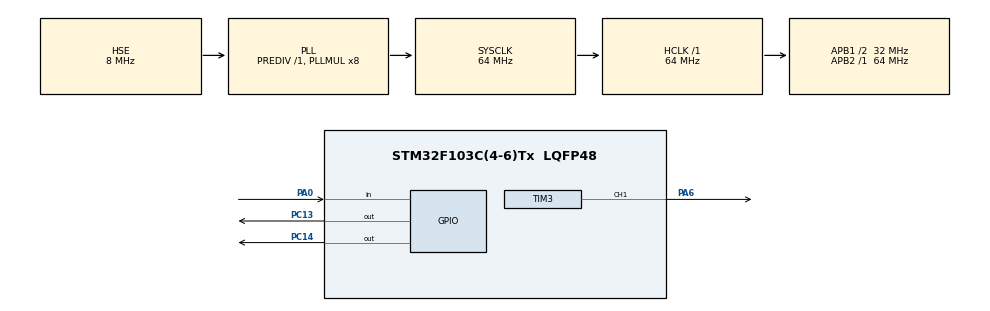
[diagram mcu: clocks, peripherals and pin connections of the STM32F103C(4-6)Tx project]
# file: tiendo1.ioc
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Mcu.Family=STM32F1
Mcu.Name=STM32F103C(4-6)Tx
Mcu.Package=LQFP48
NVIC.PriorityGroup=NVIC_PRIORITYGROUP_4
PA0-WKUP.GPIO_PuPd=GPIO_PULLUP
PA0-WKUP.Signal=GPIO_Input
PA13.Mode=Serial_Wire
PA13.Signal=SYS_JTMS-SWDIO
PA14.Mode=Serial_Wire
PA14.Signal=SYS_JTCK-SWCLK
PA6.Signal=S_TIM3_CH1
PC13-TAMPER-RTC.Signal=GPIO_Output
PC14-OSC32_IN.Signal=GPIO_Output
PD0-OSC_IN.Mode=HSE-External-Oscillator
PD0-OSC_IN.Signal=RCC_OSC_IN
PD1-OSC_OUT.Mode=HSE-External-Oscillator
PD1-OSC_OUT.Signal=RCC_OSC_OUT
ProjectManager.HeapSize=0x200
ProjectManager.StackSize=0x400
ProjectManager.TargetToolchain=MDK-ARM V5.32
RCC.AHBFreq_Value=64000000
RCC.APB1CLKDivider=RCC_HCLK_DIV2
RCC.APB1Freq_Value=32000000
RCC.APB1TimFreq_Value=64000000
RCC.APB2Freq_Value=64000000
RCC.APB2TimFreq_Value=64000000
RCC.HCLKFreq_Value=64000000
RCC.PLLMUL=RCC_PLL_MUL8
RCC.PLLSourceVirtual=RCC_PLLSOURCE_HSE
RCC.SYSCLKFreq_VALUE=64000000
RCC.SYSCLKSource=RCC_SYSCLKSOURCE_PLLCLK
RCC.USBFreq_Value=64000000
SH.S_TIM3_CH1.0=TIM3_CH1,PWM Generation1 CH1
TIM3.Channel-PWM\ Generation1\ CH1=TIM_CHANNEL_1
TIM3.Period=1999
TIM3.Prescaler=63
VP_TIM3_VS_ClockSourceINT.Mode=Internal
board=custom

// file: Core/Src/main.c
/* USER CODE BEGIN Header */
/**
  ******************************************************************************
  * @file           : main.c
  * @brief          : Main program body
  ******************************************************************************
  * @attention
  *
  * Copyright (c) 2024 STMicroelectronics.
  * All rights reserved.
  *
  * This software is licensed under terms that can be found in the LICENSE file
  * in the root directory of this software component.
  * If no LICENSE file comes with this software, it is provided AS-IS.
  *
  ******************************************************************************
  */
/* USER CODE END Header */
#include "main.h"

/* USER CODE BEGIN Includes */
#include "tiendo1.h"
/* USER CODE END Includes */

TIM_HandleTypeDef htim3;

void SystemClock_Config(void);
static void MX_GPIO_Init(void);
static void MX_TIM3_Init(void);

/* USER CODE BEGIN 0 */
tiendo1_Typedef tiendo11;
tiendo1_Typedef tiendo12;
/* USER CODE END 0 */

int main(void)
{

  /* MCU Configuration--------------------------------------------------------*/

  /* Reset of all peripherals, Initializes the Flash interface and the Systick. */
  HAL_Init();

  /* Configure the system clock */
  SystemClock_Config();

  /* Initialize all configured peripherals */
  MX_GPIO_Init();
  MX_TIM3_Init();
  /* USER CODE BEGIN 2 */
HAL_TIM_PWM_Start(&htim3,TIM_CHANNEL_1);
tiendo1_init(&tiendo11,GPIOA,GPIO_PIN_0);
  /* USER CODE END 2 */

  /* Infinite loop */
  while (1)
  {

    /* USER CODE BEGIN 3 */
	tiendo1_handle(&tiendo11);
  }
  /* USER CODE END 3 */
}

void SystemClock_Config(void)
{
  RCC_OscInitTypeDef RCC_OscInitStruct = {0};
  RCC_ClkInitTypeDef RCC_ClkInitStruct = {0};

  /** Initializes the RCC Oscillators according to the specified parameters
  * in the RCC_OscInitTypeDef structure.
  */
  RCC_OscInitStruct.OscillatorType = RCC_OSCILLATORTYPE_HSE;
  RCC_OscInitStruct.HSEState = RCC_HSE_ON;
  RCC_OscInitStruct.HSEPredivValue = RCC_HSE_PREDIV_DIV1;
  RCC_OscInitStruct.HSIState = RCC_HSI_ON;
  RCC_OscInitStruct.PLL.PLLState = RCC_PLL_ON;
  RCC_OscInitStruct.PLL.PLLSource = RCC_PLLSOURCE_HSE;
  RCC_OscInitStruct.PLL.PLLMUL = RCC_PLL_MUL8;
  if (HAL_RCC_OscConfig(&RCC_OscInitStruct) != HAL_OK)
  {
    Error_Handler();
  }

  /** Initializes the CPU, AHB and APB buses clocks
  */
  RCC_ClkInitStruct.ClockType = RCC_CLOCKTYPE_HCLK|RCC_CLOCKTYPE_SYSCLK
                              |RCC_CLOCKTYPE_PCLK1|RCC_CLOCKTYPE_PCLK2;
  RCC_ClkInitStruct.SYSCLKSource = RCC_SYSCLKSOURCE_PLLCLK;
  RCC_ClkInitStruct.AHBCLKDivider = RCC_SYSCLK_DIV1;
  RCC_ClkInitStruct.APB1CLKDivider = RCC_HCLK_DIV2;
  RCC_ClkInitStruct.APB2CLKDivider = RCC_HCLK_DIV1;

  if (HAL_RCC_ClockConfig(&RCC_ClkInitStruct, FLASH_LATENCY_2) != HAL_OK)
  {
    Error_Handler();
  }
}

static void MX_TIM3_Init(void)
{

  TIM_ClockConfigTypeDef sClockSourceConfig = {0};
  TIM_MasterConfigTypeDef sMasterConfig = {0};
  TIM_OC_InitTypeDef sConfigOC = {0};

  htim3.Instance = TIM3;
  htim3.Init.Prescaler = 63;
  htim3.Init.CounterMode = TIM_COUNTERMODE_UP;
  htim3.Init.Period = 1999;
  htim3.Init.ClockDivision = TIM_CLOCKDIVISION_DIV1;
  htim3.Init.AutoReloadPreload = TIM_AUTORELOAD_PRELOAD_DISABLE;
  if (HAL_TIM_Base_Init(&htim3) != HAL_OK)
  {
    Error_Handler();
  }
  sClockSourceConfig.ClockSource = TIM_CLOCKSOURCE_INTERNAL;
  if (HAL_TIM_ConfigClockSource(&htim3, &sClockSourceConfig) != HAL_OK)
  {
    Error_Handler();
  }
  if (HAL_TIM_PWM_Init(&htim3) != HAL_OK)
  {
    Error_Handler();
  }
  sMasterConfig.MasterOutputTrigger = TIM_TRGO_RESET;
  sMasterConfig.MasterSlaveMode = TIM_MASTERSLAVEMODE_DISABLE;
  if (HAL_TIMEx_MasterConfigSynchronization(&htim3, &sMasterConfig) != HAL_OK)
  {
    Error_Handler();
  }
  sConfigOC.OCMode = TIM_OCMODE_PWM1;
  sConfigOC.Pulse = 0;
  sConfigOC.OCPolarity = TIM_OCPOLARITY_HIGH;
  sConfigOC.OCFastMode = TIM_OCFAST_DISABLE;
  if (HAL_TIM_PWM_ConfigChannel(&htim3, &sConfigOC, TIM_CHANNEL_1) != HAL_OK)
  {
    Error_Handler();
  }
  HAL_TIM_MspPostInit(&htim3);

}

static void MX_GPIO_Init(void)
{
  GPIO_InitTypeDef GPIO_InitStruct = {0};

  /* GPIO Ports Clock Enable */
  __HAL_RCC_GPIOC_CLK_ENABLE();
  __HAL_RCC_GPIOD_CLK_ENABLE();
  __HAL_RCC_GPIOA_CLK_ENABLE();

  /*Configure GPIO pin Output Level */
  HAL_GPIO_WritePin(GPIOC, GPIO_PIN_13|GPIO_PIN_14, GPIO_PIN_RESET);

  /*Configure GPIO pins : PC13 PC14 */
  GPIO_InitStruct.Pin = GPIO_PIN_13|GPIO_PIN_14;
  GPIO_InitStruct.Mode = GPIO_MODE_OUTPUT_PP;
  GPIO_InitStruct.Pull = GPIO_NOPULL;
  GPIO_InitStruct.Speed = GPIO_SPEED_FREQ_LOW;
  HAL_GPIO_Init(GPIOC, &GPIO_InitStruct);

  /*Configure GPIO pin : PA0 */
  GPIO_InitStruct.Pin = GPIO_PIN_0;
  GPIO_InitStruct.Mode = GPIO_MODE_INPUT;
  GPIO_InitStruct.Pull = GPIO_PULLUP;
  HAL_GPIO_Init(GPIOA, &GPIO_InitStruct);

}

void Error_Handler(void)
{
  __disable_irq();
  while (1)
  {
  }
}
